# RP2350 register map
Vendor: Raspberry Pi; Series: RP; File version: 0.1
CPU: CM33 r1p0, little endian, MPU, FPU, DSP, VTOR, 4 interrupt priority bits, 52 interrupts, 8 SAU regions
Registers are 32-bit, read-write, reset 0x0 unless marked. A register's access mark holds for its fields unless they carry their own. Offsets are from the block's base; [hi:lo] are bit positions; {n}, {i} and the like mark numbered series; 'fields as' and 'values as' point back to an identical list.

## IO_QSPI
Base 0x40030000
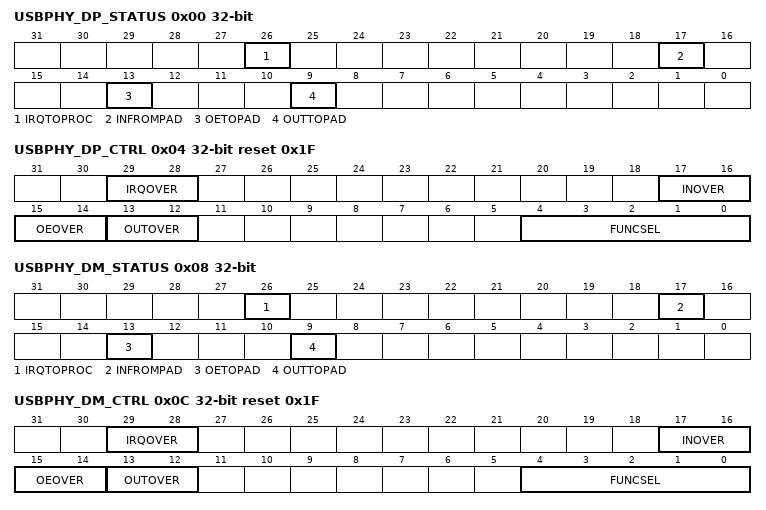
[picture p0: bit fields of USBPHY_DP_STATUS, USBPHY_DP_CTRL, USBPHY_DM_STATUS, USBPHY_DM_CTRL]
0x00 USBPHY_DP_STATUS
  [26] IRQTOPROC ro — interrupt to processors, after override is applied
  [17] INFROMPAD ro — input signal from pad, before filtering and override are applied
  [13] OETOPAD ro — output enable to pad after register override is applied
  [9] OUTTOPAD ro — output signal to pad after register override is applied
0x04 USBPHY_DP_CTRL reset 0x1F
  [29:28] IRQOVER
    0=NORMAL (don't invert the interrupt); 1=INVERT (invert the interrupt); 2=LOW (drive interrupt low); 3=HIGH (drive interrupt high)
  [17:16] INOVER
    0=NORMAL (don't invert the peri input); 1=INVERT (invert the peri input); 2=LOW (drive peri input low); 3=HIGH (drive peri input high)
  [15:14] OEOVER
    0=NORMAL (drive output enable from peripheral signal selected by funcsel); 1=INVERT (drive output enable from inverse of peripheral signal selected by funcsel); 2=DISABLE (disable output); 3=ENABLE (enable output)
  [13:12] OUTOVER
    0=NORMAL (drive output from peripheral signal selected by funcsel); 1=INVERT (drive output from inverse of peripheral signal selected by funcsel); 2=LOW (drive output low); 3=HIGH (drive output high)
  [4:0] FUNCSEL — 0-31 -> selects pin function according to the gpio table 31 == NULL
    2=uart1_tx; 3=i2c0_sda; 5=siob_proc_56; 31=null
0x08 USBPHY_DM_STATUS
  fields as USBPHY_DP_STATUS
0x0C USBPHY_DM_CTRL reset 0x1F
  [29:28] IRQOVER
    values as USBPHY_DP_CTRL.IRQOVER
  [17:16] INOVER
    values as USBPHY_DP_CTRL.INOVER
  [15:14] OEOVER
    values as USBPHY_DP_CTRL.OEOVER
  [13:12] OUTOVER
    values as USBPHY_DP_CTRL.OUTOVER
  [4:0] FUNCSEL — 0-31 -> selects pin function according to the gpio table 31 == NULL
    2=uart1_rx; 3=i2c0_scl; 5=siob_proc_57; 31=null
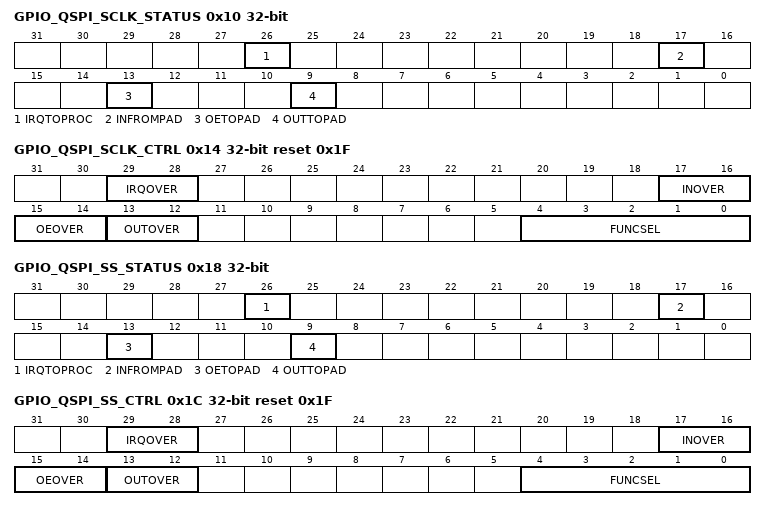
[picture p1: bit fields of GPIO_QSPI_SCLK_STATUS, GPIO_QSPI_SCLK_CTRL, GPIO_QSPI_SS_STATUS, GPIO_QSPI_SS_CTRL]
0x10 GPIO_QSPI_SCLK_STATUS
  fields as USBPHY_DP_STATUS
0x14 GPIO_QSPI_SCLK_CTRL reset 0x1F
  [29:28] IRQOVER
    values as USBPHY_DP_CTRL.IRQOVER
  [17:16] INOVER
    values as USBPHY_DP_CTRL.INOVER
  [15:14] OEOVER
    values as USBPHY_DP_CTRL.OEOVER
  [13:12] OUTOVER
    values as USBPHY_DP_CTRL.OUTOVER
  [4:0] FUNCSEL — 0-31 -> selects pin function according to the gpio table 31 == NULL
    0=xip_sclk; 2=uart1_cts; 3=i2c1_sda; 5=siob_proc_58; 11=uart1_tx; 31=null
0x18 GPIO_QSPI_SS_STATUS
  fields as USBPHY_DP_STATUS
0x1C GPIO_QSPI_SS_CTRL reset 0x1F
  [29:28] IRQOVER
    values as USBPHY_DP_CTRL.IRQOVER
  [17:16] INOVER
    values as USBPHY_DP_CTRL.INOVER
  [15:14] OEOVER
    values as USBPHY_DP_CTRL.OEOVER
  [13:12] OUTOVER
    values as USBPHY_DP_CTRL.OUTOVER
  [4:0] FUNCSEL — 0-31 -> selects pin function according to the gpio table 31 == NULL
    0=xip_ss_n_0; 2=uart1_rts; 3=i2c1_scl; 5=siob_proc_59; 11=uart1_rx; 31=null
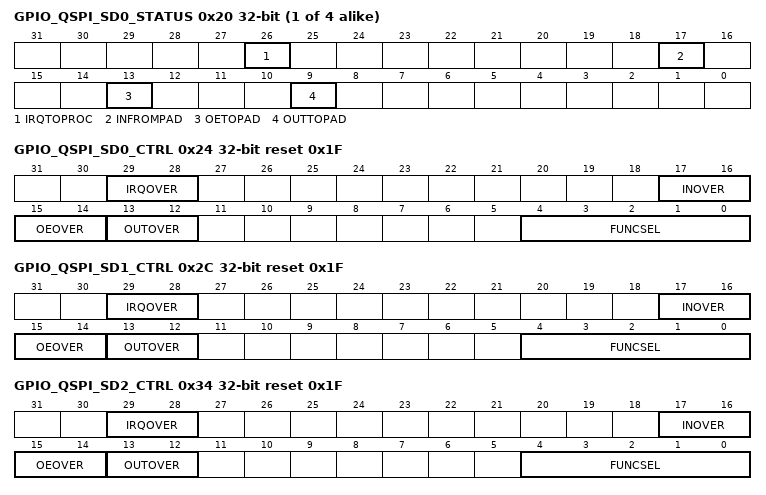
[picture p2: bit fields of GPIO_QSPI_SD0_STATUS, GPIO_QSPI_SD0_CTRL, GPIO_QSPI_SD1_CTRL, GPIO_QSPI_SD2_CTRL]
{0x20+8i} GPIO_QSPI_SD{i}_STATUS (i=0..3)
  fields as USBPHY_DP_STATUS
0x24 GPIO_QSPI_SD0_CTRL reset 0x1F
  [29:28] IRQOVER
    values as USBPHY_DP_CTRL.IRQOVER
  [17:16] INOVER
    values as USBPHY_DP_CTRL.INOVER
  [15:14] OEOVER
    values as USBPHY_DP_CTRL.OEOVER
  [13:12] OUTOVER
    values as USBPHY_DP_CTRL.OUTOVER
  [4:0] FUNCSEL — 0-31 -> selects pin function according to the gpio table 31 == NULL
    0=xip_sd0; 2=uart0_tx; 3=i2c0_sda; 5=siob_proc_60; 31=null
0x2C GPIO_QSPI_SD1_CTRL reset 0x1F
  [29:28] IRQOVER
    values as USBPHY_DP_CTRL.IRQOVER
  [17:16] INOVER
    values as USBPHY_DP_CTRL.INOVER
  [15:14] OEOVER
    values as USBPHY_DP_CTRL.OEOVER
  [13:12] OUTOVER
    values as USBPHY_DP_CTRL.OUTOVER
  [4:0] FUNCSEL — 0-31 -> selects pin function according to the gpio table 31 == NULL
    0=xip_sd1; 2=uart0_rx; 3=i2c0_scl; 5=siob_proc_61; 31=null
0x34 GPIO_QSPI_SD2_CTRL reset 0x1F
  [29:28] IRQOVER
    values as USBPHY_DP_CTRL.IRQOVER
  [17:16] INOVER
    values as USBPHY_DP_CTRL.INOVER
  [15:14] OEOVER
    values as USBPHY_DP_CTRL.OEOVER
  [13:12] OUTOVER
    values as USBPHY_DP_CTRL.OUTOVER
  [4:0] FUNCSEL — 0-31 -> selects pin function according to the gpio table 31 == NULL
    0=xip_sd2; 2=uart0_cts; 3=i2c1_sda; 5=siob_proc_62; 11=uart0_tx; 31=null
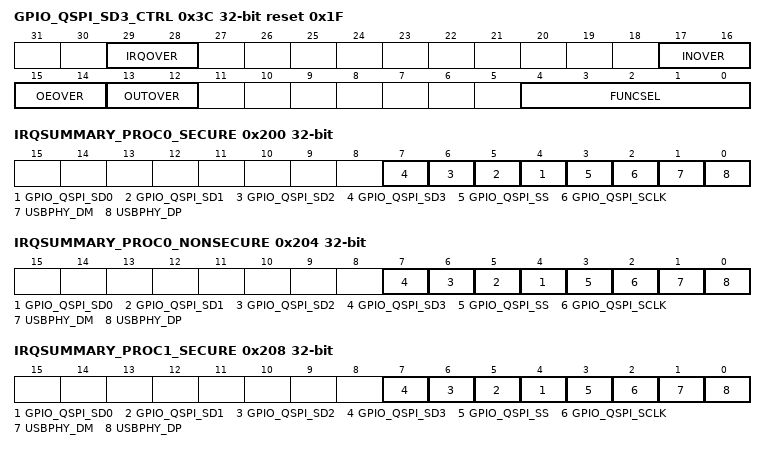
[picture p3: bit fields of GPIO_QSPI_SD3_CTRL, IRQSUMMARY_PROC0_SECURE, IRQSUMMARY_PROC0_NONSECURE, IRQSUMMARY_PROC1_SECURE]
0x3C GPIO_QSPI_SD3_CTRL reset 0x1F
  [29:28] IRQOVER
    values as USBPHY_DP_CTRL.IRQOVER
  [17:16] INOVER
    values as USBPHY_DP_CTRL.INOVER
  [15:14] OEOVER
    values as USBPHY_DP_CTRL.OEOVER
  [13:12] OUTOVER
    values as USBPHY_DP_CTRL.OUTOVER
  [4:0] FUNCSEL — 0-31 -> selects pin function according to the gpio table 31 == NULL
    0=xip_sd3; 2=uart0_rts; 3=i2c1_scl; 5=siob_proc_63; 11=uart0_rx; 31=null
0x200 IRQSUMMARY_PROC0_SECURE
  [n+4] GPIO_QSPI_SD{n} ro (n=0..3), [3] GPIO_QSPI_SS ro, [2] GPIO_QSPI_SCLK ro, [1] USBPHY_DM ro, [0] USBPHY_DP ro
0x204 IRQSUMMARY_PROC0_NONSECURE
  fields as IRQSUMMARY_PROC0_SECURE
0x208 IRQSUMMARY_PROC1_SECURE
  fields as IRQSUMMARY_PROC0_SECURE
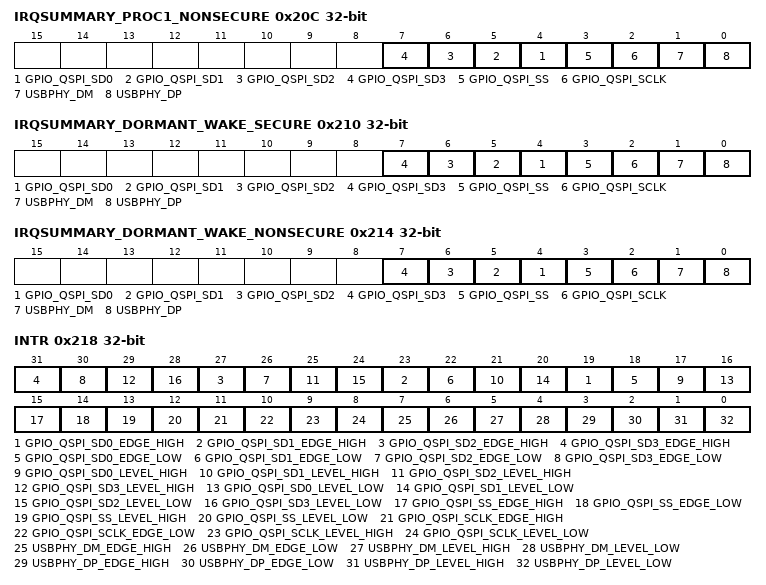
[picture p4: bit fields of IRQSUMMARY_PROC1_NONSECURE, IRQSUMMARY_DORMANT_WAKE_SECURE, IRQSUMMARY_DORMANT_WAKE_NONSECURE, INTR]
0x20C IRQSUMMARY_PROC1_NONSECURE
  fields as IRQSUMMARY_PROC0_SECURE
0x210 IRQSUMMARY_DORMANT_WAKE_SECURE
  fields as IRQSUMMARY_PROC0_SECURE
0x214 IRQSUMMARY_DORMANT_WAKE_NONSECURE
  fields as IRQSUMMARY_PROC0_SECURE
0x218 INTR — Raw Interrupts
  [4n+19] GPIO_QSPI_SD{n}_EDGE_HIGH write-1-clears (n=0..3), [4n+18] GPIO_QSPI_SD{n}_EDGE_LOW write-1-clears (n=0..3), [4n+17] GPIO_QSPI_SD{n}_LEVEL_HIGH ro (n=0..3), [4n+16] GPIO_QSPI_SD{n}_LEVEL_LOW ro (n=0..3), [15] GPIO_QSPI_SS_EDGE_HIGH write-1-clears, [14] GPIO_QSPI_SS_EDGE_LOW write-1-clears, [13] GPIO_QSPI_SS_LEVEL_HIGH ro, [12] GPIO_QSPI_SS_LEVEL_LOW ro, [11] GPIO_QSPI_SCLK_EDGE_HIGH write-1-clears, [10] GPIO_QSPI_SCLK_EDGE_LOW write-1-clears, [9] GPIO_QSPI_SCLK_LEVEL_HIGH ro, [8] GPIO_QSPI_SCLK_LEVEL_LOW ro, [7] USBPHY_DM_EDGE_HIGH write-1-clears, [6] USBPHY_DM_EDGE_LOW write-1-clears, [5] USBPHY_DM_LEVEL_HIGH ro, [4] USBPHY_DM_LEVEL_LOW ro, [3] USBPHY_DP_EDGE_HIGH write-1-clears, [2] USBPHY_DP_EDGE_LOW write-1-clears, [1] USBPHY_DP_LEVEL_HIGH ro, [0] USBPHY_DP_LEVEL_LOW ro
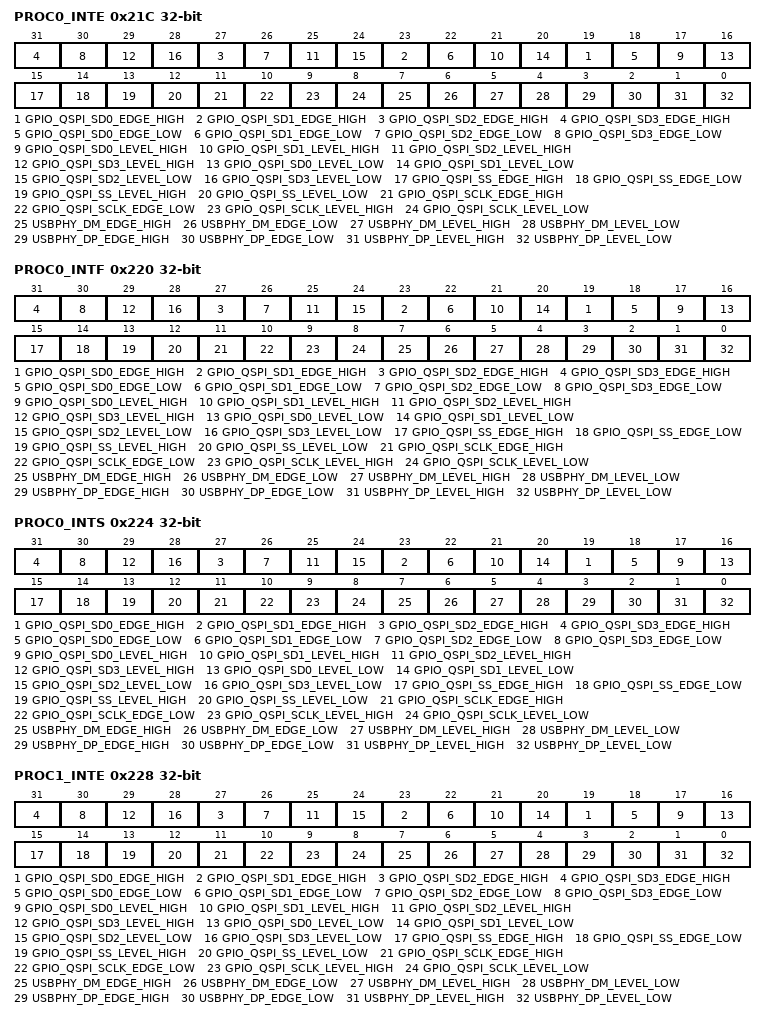
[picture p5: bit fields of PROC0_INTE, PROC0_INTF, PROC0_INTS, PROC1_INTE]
0x21C PROC0_INTE — Interrupt Enable for proc0
  [4n+19] GPIO_QSPI_SD{n}_EDGE_HIGH (n=0..3), [4n+18] GPIO_QSPI_SD{n}_EDGE_LOW (n=0..3), [4n+17] GPIO_QSPI_SD{n}_LEVEL_HIGH (n=0..3), [4n+16] GPIO_QSPI_SD{n}_LEVEL_LOW (n=0..3), [15] GPIO_QSPI_SS_EDGE_HIGH, [14] GPIO_QSPI_SS_EDGE_LOW, [13] GPIO_QSPI_SS_LEVEL_HIGH, [12] GPIO_QSPI_SS_LEVEL_LOW, [11] GPIO_QSPI_SCLK_EDGE_HIGH, [10] GPIO_QSPI_SCLK_EDGE_LOW, [9] GPIO_QSPI_SCLK_LEVEL_HIGH, [8] GPIO_QSPI_SCLK_LEVEL_LOW, [7] USBPHY_DM_EDGE_HIGH, [6] USBPHY_DM_EDGE_LOW, [5] USBPHY_DM_LEVEL_HIGH, [4] USBPHY_DM_LEVEL_LOW, [3] USBPHY_DP_EDGE_HIGH, [2] USBPHY_DP_EDGE_LOW, [1] USBPHY_DP_LEVEL_HIGH, [0] USBPHY_DP_LEVEL_LOW
0x220 PROC0_INTF — Interrupt Force for proc0
  fields as PROC0_INTE
0x224 PROC0_INTS — Interrupt status after masking & forcing for proc0
  [4n+19] GPIO_QSPI_SD{n}_EDGE_HIGH ro (n=0..3), [4n+18] GPIO_QSPI_SD{n}_EDGE_LOW ro (n=0..3), [4n+17] GPIO_QSPI_SD{n}_LEVEL_HIGH ro (n=0..3), [4n+16] GPIO_QSPI_SD{n}_LEVEL_LOW ro (n=0..3), [15] GPIO_QSPI_SS_EDGE_HIGH ro, [14] GPIO_QSPI_SS_EDGE_LOW ro, [13] GPIO_QSPI_SS_LEVEL_HIGH ro, [12] GPIO_QSPI_SS_LEVEL_LOW ro, [11] GPIO_QSPI_SCLK_EDGE_HIGH ro, [10] GPIO_QSPI_SCLK_EDGE_LOW ro, [9] GPIO_QSPI_SCLK_LEVEL_HIGH ro, [8] GPIO_QSPI_SCLK_LEVEL_LOW ro, [7] USBPHY_DM_EDGE_HIGH ro, [6] USBPHY_DM_EDGE_LOW ro, [5] USBPHY_DM_LEVEL_HIGH ro, [4] USBPHY_DM_LEVEL_LOW ro, [3] USBPHY_DP_EDGE_HIGH ro, [2] USBPHY_DP_EDGE_LOW ro, [1] USBPHY_DP_LEVEL_HIGH ro, [0] USBPHY_DP_LEVEL_LOW ro
0x228 PROC1_INTE — Interrupt Enable for proc1
  fields as PROC0_INTE
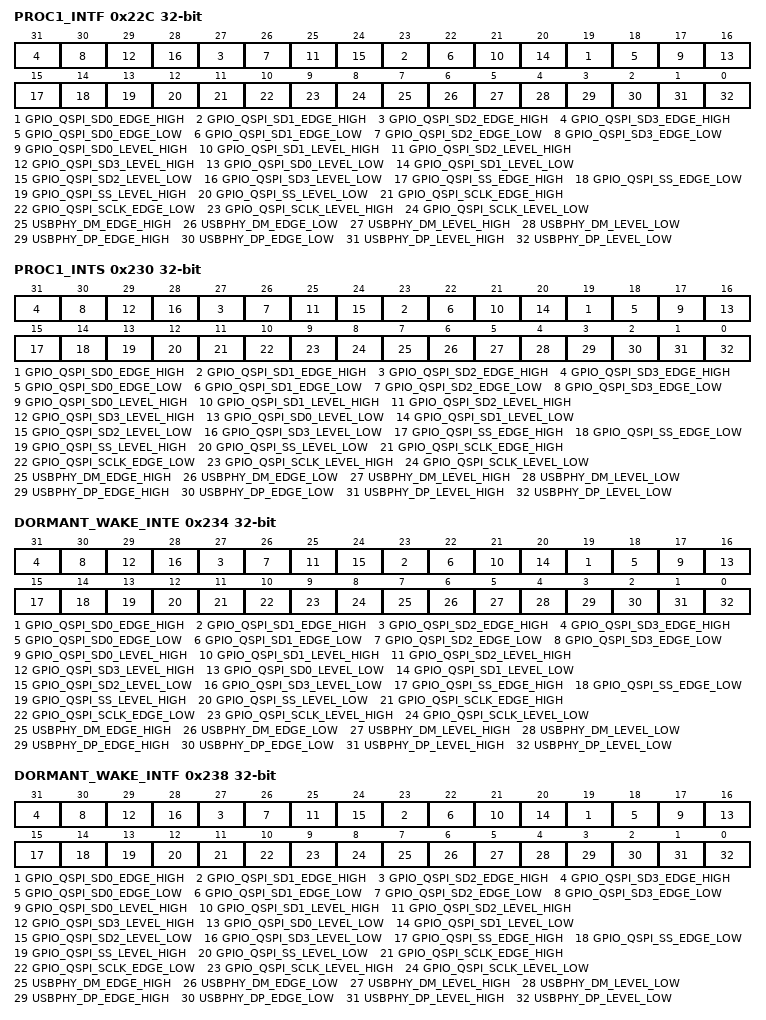
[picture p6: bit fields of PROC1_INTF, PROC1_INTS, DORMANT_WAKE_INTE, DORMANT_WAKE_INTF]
0x22C PROC1_INTF — Interrupt Force for proc1
  fields as PROC0_INTE
0x230 PROC1_INTS — Interrupt status after masking & forcing for proc1
  fields as PROC0_INTS
0x234 DORMANT_WAKE_INTE — Interrupt Enable for dormant_wake
  fields as PROC0_INTE
0x238 DORMANT_WAKE_INTF — Interrupt Force for dormant_wake
  fields as PROC0_INTE
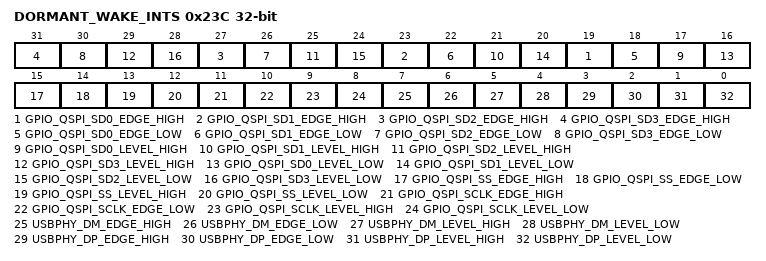
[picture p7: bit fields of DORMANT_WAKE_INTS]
0x23C DORMANT_WAKE_INTS — Interrupt status after masking & forcing for dormant_wake
  fields as PROC0_INTS
